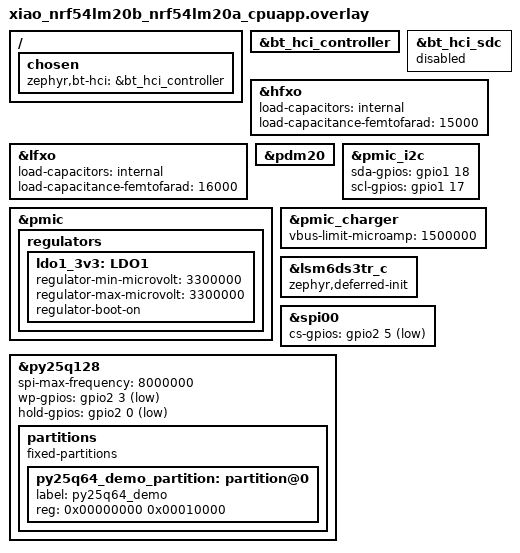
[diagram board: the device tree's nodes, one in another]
/* BLE: use open-source LL controller (SDC not available in PlatformIO Zephyr) */
/ {
	chosen {
		zephyr,bt-hci = &bt_hci_controller;
	};
};

&bt_hci_controller {
	status = "okay";
};

&bt_hci_sdc {
	status = "disabled";
};

&hfxo {
	load-capacitors = "internal";
	load-capacitance-femtofarad = <15000>;
	status = "okay";
};

&lfxo {
	load-capacitors = "internal";
	load-capacitance-femtofarad = <16000>;
	status = "okay";
};

/* PDM Microphone */
dmic_dev: &pdm20 {
	status = "okay";
};

/* PMIC GPIO-I2C bus: SDA=P1.18, SCL=P1.17 */
&pmic_i2c {
	sda-gpios = <&gpio1 18 GPIO_ACTIVE_HIGH>;
	scl-gpios = <&gpio1 17 GPIO_ACTIVE_HIGH>;
	status = "okay";
};

/* PMIC regulators - LDO1 powers both DMIC and IMU (3.3V) */
&pmic {
	regulators {
		ldo1_3v3: LDO1 {
			regulator-min-microvolt = <3300000>;
			regulator-max-microvolt = <3300000>;
			regulator-boot-on;
		};
	};
};

/* NPM1300 charger: set VBUS current limit to 1.5A */
npm1300_ek_pmic: &pmic {};
npm1300_ek_charger: &pmic_charger {
	vbus-limit-microamp = <1500000>;
};

/* IMU - deferred init (manual power-up via LDO1) */
&lsm6ds3tr_c {
	zephyr,deferred-init;
};

/* External SPI Flash */
&spi00 {
	status = "okay";
	cs-gpios = <&gpio2 5 GPIO_ACTIVE_LOW>;
};

&py25q128 {
	status = "okay";
	spi-max-frequency = <8000000>;
	wp-gpios = <&gpio2 3 GPIO_ACTIVE_LOW>;
	hold-gpios = <&gpio2 0 GPIO_ACTIVE_LOW>;

	partitions {
		compatible = "fixed-partitions";
		#address-cells = <1>;
		#size-cells = <1>;

		py25q64_demo_partition: partition@0 {
			label = "py25q64_demo";
			reg = <0x00000000 0x00010000>;
		};
	};
};
